# M460 register map
File version: 1.0
Registers are 32-bit, read-write, reset 0x0 unless marked. A register's access mark holds for its fields unless they carry their own. Offsets are from the block's base; [hi:lo] are bit positions; {n}, {i} and the like mark numbered series.

## EBI — EBI Register Map
Base 0x40010000
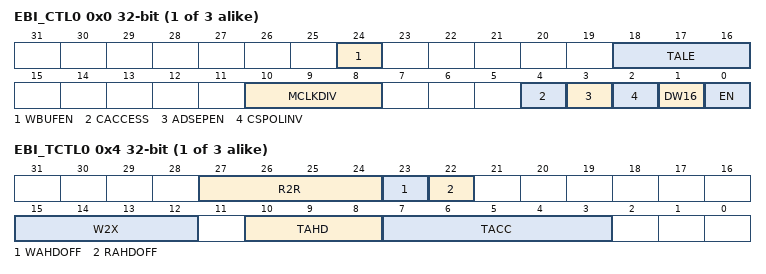
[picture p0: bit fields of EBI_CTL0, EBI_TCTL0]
{0x0+0x10*i} EBI_CTL{i} (i=0..2) — External Bus Interface Bank{i} Control Register
  [24] WBUFEN — EBI Write Buffer Enable Bit. Note: This bit is only available in EBI_CTL0 register.
    0=EBI write buffer Disabled; 1=EBI write buffer Enabled
  [18:16] TALE — Extend Time of ALE. The EBI_ALE high pulse period (tALE) to latch the address can be controlled by TALE. Note: This field is only available in EBI_CTL0 register.
  [10:8] MCLKDIV — External Output Clock Divider. The frequency of EBI output clock (MCLK) is controlled by MCLKDIV as follow:
    0=HCLK/1; 1=HCLK/2; 2=HCLK/4; 3=HCLK/8; 4=HCLK/16; 5=HCLK/32; 6=HCLK/64; 7=HCLK/128
  [4] CACCESS — Continuous Data Access Mode. When continuous access mode enabled, the tASU, tALE and tLHD cycles are bypass for continuous data transfer request.
    0=Continuous data access mode Disabled; 1=Continuous data access mode Enabled
  [3] ADSEPEN — EBI Address/Data Bus Separate Mode Enable Bit
    0=Address/Data Bus Separate Mode Disabled; 1=Address/Data Bus Separate Mode Enabled
  [2] CSPOLINV — Chip Select Pin Polar Inverse. This bit defines the active level of EBI chip select pin (EBI_nCS).
    0=Chip select pin (EBI_nCS) is active low; 1=Chip select pin (EBI_nCS) is active high
  [1] DW16 — EBI Data Width 16-bit Select. This bit defines if the EBI data width is 8-bit or 16-bit.
    0=EBI data width is 8-bit; 1=EBI data width is 16-bit
  [0] EN — EBI Enable Bit. This bit is the functional enable bit for EBI.
    0=EBI function Disabled; 1=EBI function Enabled
{0x4+0x10*i} EBI_TCTL{i} (i=0..2) — External Bus Interface Bank{i} Timing Control Register
  [27:24] R2R — Idle Cycle Between Read-to-read. This field defines the number of R2R idle cycle. When read action is finished and the next action is going to read, R2R idle cycle is inserted and EBI_nCS return to idle state.
  [23] WAHDOFF — Access Hold Time Disable Control When Write
    0=Data Access Hold Time (tAHD) during EBI writing Enabled; 1=Data Access Hold Time (tAHD) during EBI writing Disabled
  [22] RAHDOFF — Access Hold Time Disable Control When Read
    0=Data Access Hold Time (tAHD) during EBI reading Enabled; 1=Data Access Hold Time (tAHD) during EBI reading Disabled
  [15:12] W2X — Idle Cycle After Write. This field defines the number of W2X idle cycle. When write action is finished, W2X idle cycle is inserted and EBI_nCS return to idle state.
  [10:8] TAHD — EBI Data Access Hold Time. TAHD defines data access hold time (tAHD).
  [7:3] TACC — EBI Data Access Time. TACC defines data access time (tACC).

## GPIOINT — GPIO Register Map
Base 0x40004450
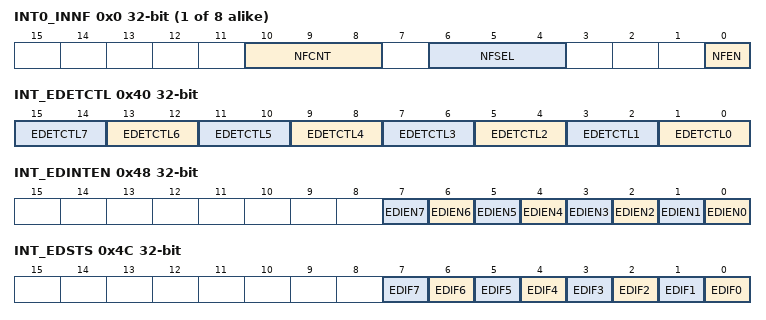
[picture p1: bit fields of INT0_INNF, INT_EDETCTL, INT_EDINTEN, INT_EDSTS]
{0x0+4i} INT{i}_INNF (i=0..7) — INT{i} Input Noise Filter Register
  [10:8] NFCNT — Noise Filter Count. The register bits control the filter counter to count from 0 to NFCNT.
  [6:4] NFSEL — Noise Filter Clock Selection
    0=Filter clock is HCLK; 1=Filter clock is HCLK/2; 2=Filter clock is HCLK/4; 3=Filter clock is HCLK/8; 4=Filter clock is HCLK/16; 5=Filter clock is HCLK/32; 6=Filter clock is HCLK/64; 7=Filter clock is HCLK/128
  [0] NFEN — Noise Filter Enable
    0=Noise Filter function Disabled; 1=Noise Filter function Enabled
0x40 INT_EDETCTL — INT Edge Detect Control Register
  [all] fields
    0=Not detect; 1=INTn low to high detection Enable; 2=INTn high to low detection Enable; 3=INTn both low to high and high to low detection Enable
  [2n+1:2n] EDETCTL{n} (n=0..7) — INTn Edge Detect Control Bits
0x48 INT_EDINTEN — INT Edge Detect Interrupt Enable Control Register
  [all] fields
    0=INTn Edge Detect Interrupt Disable; 1=INTn Edge Detect Interrupt Enable
  [n] EDIEN{n} (n=0..7) — INTn Edge Detect Interrupt Enable Bit
0x4C INT_EDSTS — INT Edge Detect Interrupt Flag Register
  [all] fields
    0=No Edge Detection happened; 1=Rising Edge or Falling edge has been detected
  [n] EDIF{n} (n=0..7) — INTn Edge Detect Interrupt Flag. Note: This bit is cleared by writing 1 to it.
